# STM32L15xxxA register map
File version: 1.0
CPU: 
Registers are 32-bit, read-write, reset 0x0 unless marked. A register's access mark holds for its fields unless they carry their own. Offsets are from the block's base; lines under a group give offsets from that group; [hi:lo] are bit positions; {n}, {i} and the like mark numbered series; 'fields as' and 'values as' point back to an identical list; <NAME> marks a mode.

## Memory map
0x40000000 TIM2 size 0x400 — General-purpose timers
0x40000400 TIM3 size 0x400 — General-purpose timers
0x40000800 TIM4 size 0x400 — General-purpose timers
0x40001000 TIM6 size 0x400 — Basic timers
0x40001400 TIM7 size 0x400 — Basic timers
0x40002400 LCD size 0x400 — Liquid crystal display controller
0x40002800 RTC size 0x400 — Real-time clock
0x40002C00 WWDG size 0x400 — Window watchdog
0x40003000 IWDG size 0x400 — Independent watchdog
0x40003800 SPI2 size 0x400 — Serial peripheral interface
0x40004400 USART2 size 0x400 — Universal synchronous asynchronous receiver transmitter
0x40004800 USART3 size 0x400 — Universal synchronous asynchronous receiver transmitter
0x40005400 I2C1 size 0x400 — Inter-integrated circuit
0x40005800 I2C2 size 0x400 — Inter-integrated circuit
0x40005C00 USB size 0x400 — Universal serial bus full-speed device interface
0x40006000 USB_SRAM size 0x400 — Universal serial bus full-speed device interface
0x40007000 PWR size 0x400 — Power control
0x40007400 DAC size 0x400 — Digital-to-analog converter
0x40007C00 COMP size 0x400 — Comparators
0x40007C04 RI size 0x400 — Routing interface
0x40010000 SYSCFG size 0x400 — System configuration controller
0x40010400 EXTI size 0x400 — External interrupt/event controller
0x40010800 TIM9 size 0x400 — General-purpose timers
0x40010C00 TIM10 size 0x400 — General-purpose timers
0x40011000 TIM11 size 0x400 — General-purpose timers
0x40012400 ADC size 0x400 — Analog-to-digital converter
0x40012700 C_ADC size 0x400 — Common ADC registers
0x40013000 SPI1 size 0x400 — Serial peripheral interface
0x40013800 USART1 size 0x400 — Universal synchronous asynchronous receiver transmitter
0x40020000 GPIOA size 0x400 — General-purpose I/Os
0x40020400 GPIOB size 0x400 — General-purpose I/Os
0x40020800 GPIOC size 0x400 — General-purpose I/Os
0x40020C00 GPIOD size 0x400 — General-purpose I/Os
0x40021000 GPIOE size 0x400 — General-purpose I/Os
0x40021400 GPIOH size 0x400 — General-purpose I/Os
0x40023000 CRC size 0x400 — CRC calculation unit
0x40023800 RCC size 0x400 — Reset and clock control
0x40023C00 Flash size 0x400
0x40026000 DMA1 size 0x400 — Direct memory access controller
0xE000E000 NVIC size 0x1001 — Nested Vectored Interrupt Controller
0xE0042000 DBG size 0x400 — Debug support

## Interrupts
1 PVD (SPI1)
2 TAMPER_STAMP (Flash)
3 RTC_WKUP (TIM10)
4 FLASH (GPIOA)
5 RCC (SPI2)
6 EXTI0 (Flash)
7 EXTI1 (Flash)
8 EXTI2 (Flash)
9 EXTI3 (Flash)
10 EXTI4 (Flash)
11 DMA1_Channel1 (DMA1)
12 DMA1_Channel2 (DMA1)
13 DMA1_Channel3 (DMA1)
14 DMA1_Channel4 (DMA1)
15 DMA1_Channel5 (DMA1)
16 DMA1_Channel6 (DMA1)
17 DMA1_Channel7 (DMA1)
21 DAC
22 COMP_CA (COMP)
23 EXTI9_5 (Flash)
24 LCD (RI)
25 TIM9 (WWDG)
26 TIM10 (TIM6)
27 TIM11 (TIM7)
28 TIM2 (TIM9)
29 TIM3 (USART1)
30 TIM4 (USART2)
31 I2C1_EV (LCD)
32 I2C1_ER (LCD)
33 I2C2_EV (PWR)
34 I2C2_ER (PWR)
35 SPI1 (TIM11)
36 SPI2 (TIM2, TIM4)
37 USART1 (ADC)
38 USART2 (NVIC)
39 USART3 (DBG)
40 EXTI15_10 (Flash)
41 RTC_Alarm (TIM10)
43 TIM6 (USB)
44 TIM7 (USB_SRAM)
45 TIM5 (USART3)
46 SPI3 (TIM3)
47 DMA2_CH1 (EXTI)
48 DMA2_CH2 (EXTI)
49 DMA2_CH3 (EXTI)
50 DMA2_CH4 (EXTI)
51 DMA2_CH5 (EXTI)
53 COMP_ACQ (COMP)

## C_ADC — Common ADC registers
Base 0x40012700
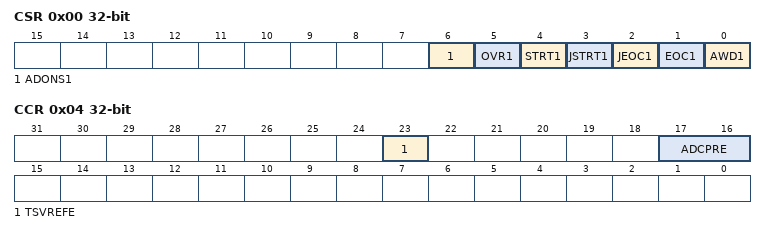
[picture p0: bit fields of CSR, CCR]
0x00 CSR ro — ADC Common status register
  [6] ADONS1 — ADON Status of ADC
  [5] OVR1 — Overrun flag of ADC 1
  [4] STRT1 — Regular channel Start flag of ADC 1
  [3] JSTRT1 — Injected channel Start flag of ADC 1
  [2] JEOC1 — Injected channel end of conversion of ADC 1
  [1] EOC1 — End of conversion of ADC 1
  [0] AWD1 — Analog watchdog flag of ADC 1
0x04 CCR — ADC common control register
  [23] TSVREFE — Temperature sensor and VREFINT enable
  [17:16] ADCPRE — ADC prescaler
